# MK20D5 register map
Vendor: Freescale Semiconductor, Inc.; Series: Kinetis_K; File version: 1.6
CPU: CM4 r0p1, little endian, no MPU, no FPU, VTOR, 4 interrupt priority bits
Registers are 32-bit, read-write, reset 0x0 unless marked. A register's access mark holds for its fields unless they carry their own. Offsets are from the block's base; [hi:lo] are bit positions; {n}, {i} and the like mark numbered series; 'fields as' and 'values as' point back to an identical list.

## PORTA — Pin Control and Interrupts
Base 0x40049000; register names take the prefix PORTA_
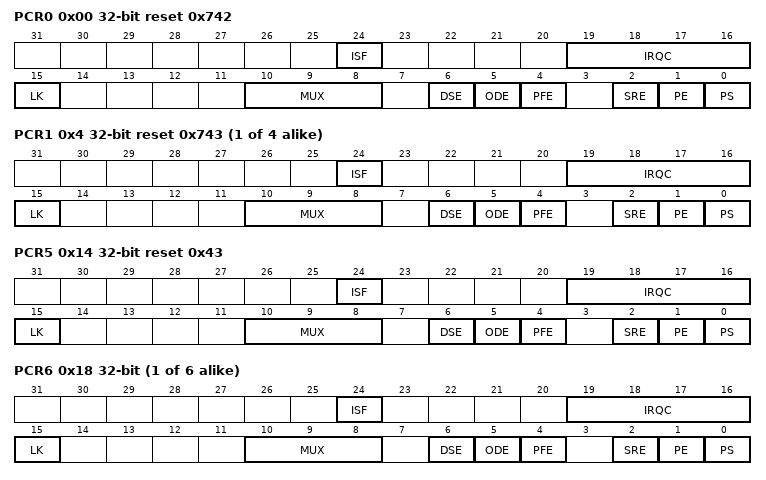
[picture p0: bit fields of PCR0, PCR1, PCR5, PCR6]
0x00 PCR0 reset 0x742 — Pin Control Register n
  [24] ISF — Interrupt Status Flag
    0=Configured interrupt has not been detected; 1=Configured interrupt has been detected. If pin is configured to generate a DMA request then the corresponding flag will be cleared automatically at the completion of the requested DMA transfer, otherwise the flag remains set until a logic one is written to that flag. If configured for a level sensitive interrupt that remains asserted then flag will set again immediately.
  [19:16] IRQC — Interrupt Configuration
    0=Interrupt/DMA Request disabled; 1=DMA Request on rising edge; 2=DMA Request on falling edge; 3=DMA Request on either edge; 8=Interrupt when logic zero; 9=Interrupt on rising edge; 10=Interrupt on falling edge; 11=Interrupt on either edge; 12=Interrupt when logic one
  [15] LK — Lock Register
    0=Pin Control Register bits [15:0] are not locked; 1=Pin Control Register bits [15:0] are locked and cannot be updated until the next System Reset
  [10:8] MUX — Pin Mux Control
    0=Pin Disabled (Analog); 1=Alternative 1 (GPIO); {v}=Alternative {v} (chip specific) (v=2..6); 7=Alternative 7 (chip specific / JTAG / NMI)
  [6] DSE — Drive Strength Enable
    0=Low drive strength is configured on the corresponding pin, if pin is configured as a digital output; 1=High drive strength is configured on the corresponding pin, if pin is configured as a digital output
  [5] ODE — Open Drain Enable
    0=Open Drain output is disabled on the corresponding pin; 1=Open Drain output is enabled on the corresponding pin, provided pin is configured as a digital output
  [4] PFE — Passive Filter Enable
    0=Passive Input Filter is disabled on the corresponding pin; 1=Passive Input Filter is enabled on the corresponding pin, provided pin is configured as a digital input. A low pass filter (10 MHz to 30 MHz bandwidth) is enabled on the digital input path. Disable the Passive Input Filter when supporting high speed interfaces (> 2 MHz) on the pin.
  [2] SRE — Slew Rate Enable
    0=Fast slew rate is configured on the corresponding pin, if pin is configured as a digital output; 1=Slow slew rate is configured on the corresponding pin, if pin is configured as a digital output
  [1] PE — Pull Enable
    0=Internal pull-up or pull-down resistor is not enabled on the corresponding pin; 1=Internal pull-up or pull-down resistor is enabled on the corresponding pin, provided pin is configured as a digital input
  [0] PS — Pull Select
    0=Internal pull-down resistor is enabled on the corresponding pin, if the corresponding Port Pull Enable Register bit is set; 1=Internal pull-up resistor is enabled on the corresponding pin, if the corresponding Port Pull Enable Register bit is set
{0x0+4i} PCR{i} reset 0x743 (i=1..4) — Pin Control Register n
  fields as PCR0
0x14 PCR5 reset 0x43 — Pin Control Register n
  fields as PCR0
{0x0+4i} PCR{i} (i=6..11) — Pin Control Register n
  [24] ISF — Interrupt Status Flag
    values as PCR0.ISF
  [19:16] IRQC — Interrupt Configuration
    values as PCR0.IRQC
  [15] LK — Lock Register
    values as PCR0.LK
  [10:8] MUX — Pin Mux Control
    values as PCR0.MUX
  [6] DSE ro — Drive Strength Enable
    values as PCR0.DSE
  [5] ODE ro — Open Drain Enable
    values as PCR0.ODE
  [4] PFE ro — Passive Filter Enable
    values as PCR0.PFE
  [2] SRE ro — Slew Rate Enable
    values as PCR0.SRE
  [1] PE ro — Pull Enable
    values as PCR0.PE
  [0] PS ro — Pull Select
    values as PCR0.PS
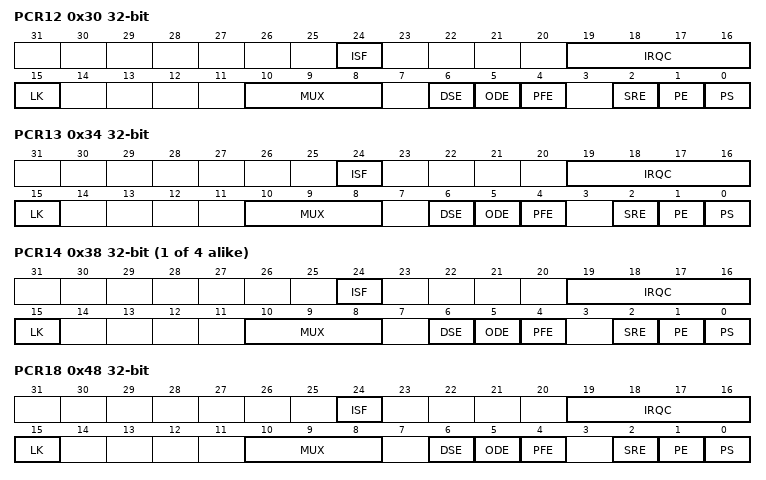
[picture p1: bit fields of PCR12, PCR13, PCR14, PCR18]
0x30 PCR12 — Pin Control Register n
  fields as PCR0
0x34 PCR13 — Pin Control Register n
  fields as PCR0
{0x0+4i} PCR{i} (i=14..17) — Pin Control Register n
  fields as PCR6
0x48 PCR18 — Pin Control Register n
  fields as PCR0
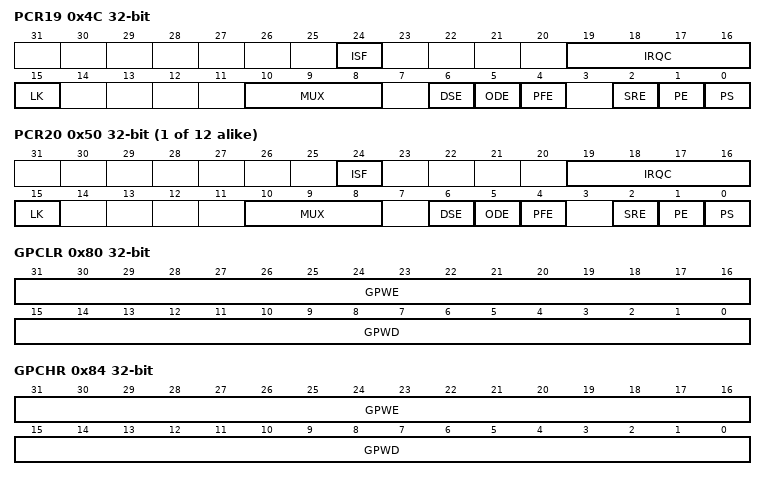
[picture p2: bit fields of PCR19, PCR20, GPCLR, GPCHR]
0x4C PCR19 — Pin Control Register n
  fields as PCR0
{0x0+4i} PCR{i} (i=20..31) — Pin Control Register n
  fields as PCR6
0x80 GPCLR wo — Global Pin Control Low Register
  [31:16] GPWE — Global Pin Write Enable
  [15:0] GPWD — Global Pin Write Data
0x84 GPCHR wo — Global Pin Control High Register
  fields as GPCLR
0xA0 ISFR — Interrupt Status Flag Register
  [31:0] ISF — Interrupt Status Flag
    0=Configured interrupt has not been detected; 1=Configured interrupt has been detected. If pin is configured to generate a DMA request then the corresponding flag will be cleared automatically at the completion of the requested DMA transfer, otherwise the flag remains set until a logic one is written to the flag. If configured for a level sensitive interrupt and the pin remains asserted then the flag will set again immediately after it is cleared.

## PORTB — Pin Control and Interrupts
Base 0x4004A000; register names take the prefix PORTB_
Registers as PORTA; these are added or differ:
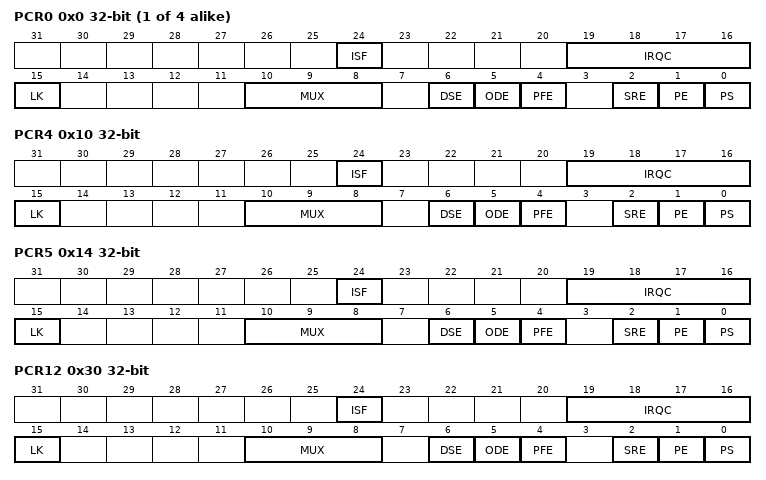
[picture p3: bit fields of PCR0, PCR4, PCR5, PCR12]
{0x0+4i} PCR{i} (i=0..3) — Pin Control Register n
  fields as PORTA.PCR0
0x10 PCR4 — Pin Control Register n
  fields as PORTA.PCR6
0x14 PCR5 — Pin Control Register n
  fields as PORTA.PCR6
0x30 PCR12 — Pin Control Register n
  fields as PORTA.PCR6
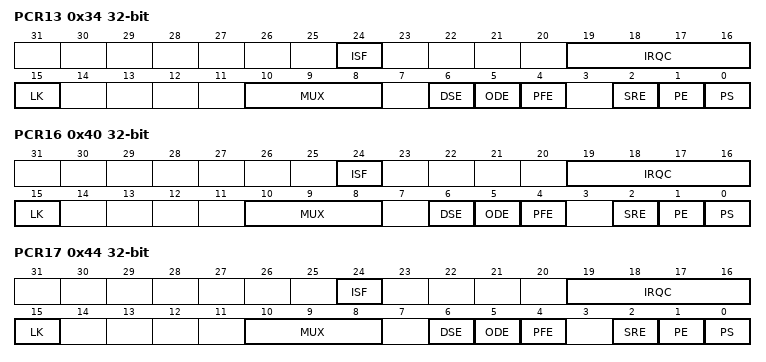
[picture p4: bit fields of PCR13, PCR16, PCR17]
0x34 PCR13 — Pin Control Register n
  fields as PORTA.PCR6
0x40 PCR16 — Pin Control Register n
  fields as PORTA.PCR0
0x44 PCR17 — Pin Control Register n
  fields as PORTA.PCR0

## PORTC — Pin Control and Interrupts
Base 0x4004B000; register names take the prefix PORTC_
Registers as PORTB; these are added or differ:
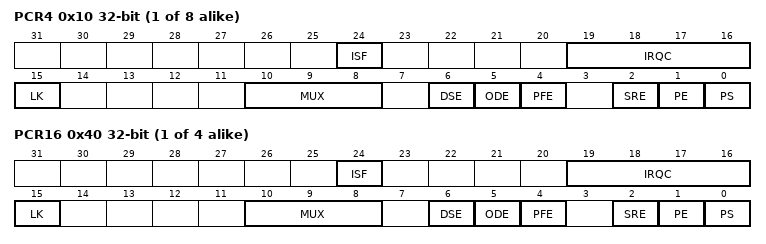
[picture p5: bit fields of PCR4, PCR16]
{0x0+4i} PCR{i} (i=4..11) — Pin Control Register n
  fields as PORTA.PCR0
{0x0+4i} PCR{i} (i=16..19) — Pin Control Register n
  fields as PORTA.PCR6

## PORTD — Pin Control and Interrupts
Base 0x4004C000; register names take the prefix PORTD_
Registers as PORTC; these are added or differ:
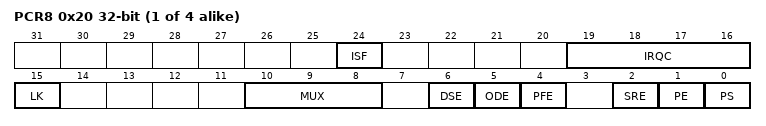
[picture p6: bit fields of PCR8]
{0x0+4i} PCR{i} (i=8..11) — Pin Control Register n
  fields as PORTA.PCR6
0xC0 DFER — Digital Filter Enable Register
  [31:0] DFE — Digital Filter Enable
    0=Digital Filter is disabled on the corresponding pin and output of the digital filter is reset to zero.Each bit in the field enables the digital filter of the same number as the bit; 1=Digital Filter is enabled on the corresponding pin, provided pin is configured as a digital input
0xC4 DFCR — Digital Filter Clock Register
  [0] CS — Clock Source
    0=Digital Filters are clocked by the bus clock; 1=Digital Filters are clocked by the 1 kHz LPO clock
0xC8 DFWR — Digital Filter Width Register
  [4:0] FILT — Filter Length

## PORTE — Pin Control and Interrupts
Base 0x4004D000; register names take the prefix PORTE_
Registers as PORTD, without DFER, DFCR, DFWR; these are added or differ:
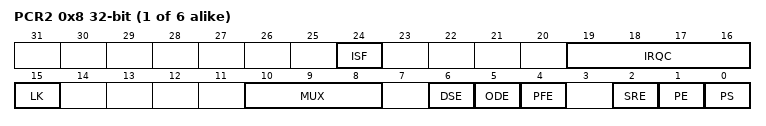
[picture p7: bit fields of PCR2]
{0x0+4i} PCR{i} (i=2..7) — Pin Control Register n
  fields as PORTA.PCR6

## Notices in the file
Redistribution and use in source and binary forms, with or without modification,
are permitted provided that the following conditions are met:
o Redistributions of source code must retain the above copyright notice, this list
of conditions and the following disclaimer.
o Redistributions in binary form must reproduce the above copyright notice, this
list of conditions and the following disclaimer in the documentation and/or
other materials provided with the distribution.
o Neither the name of Freescale Semiconductor, Inc. nor the names of its
contributors may be used to endorse or promote products derived from this
software without specific prior written permission.
THIS SOFTWARE IS PROVIDED BY THE COPYRIGHT HOLDERS AND CONTRIBUTORS "AS IS" AND
ANY EXPRESS OR IMPLIED WARRANTIES, INCLUDING, BUT NOT LIMITED TO, THE IMPLIED
WARRANTIES OF MERCHANTABILITY AND FITNESS FOR A PARTICULAR PURPOSE ARE
DISCLAIMED. IN NO EVENT SHALL THE COPYRIGHT HOLDER OR CONTRIBUTORS BE LIABLE FOR
ANY DIRECT, INDIRECT, INCIDENTAL, SPECIAL, EXEMPLARY, OR CONSEQUENTIAL DAMAGES
(INCLUDING, BUT NOT LIMITED TO, PROCUREMENT OF SUBSTITUTE GOODS OR SERVICES;
LOSS OF USE, DATA, OR PROFITS; OR BUSINESS INTERRUPTION) HOWEVER CAUSED AND ON
ANY THEORY OF LIABILITY, WHETHER IN CONTRACT, STRICT LIABILITY, OR TORT
(INCLUDING NEGLIGENCE OR OTHERWISE) ARISING IN ANY WAY OUT OF THE USE OF THIS
SOFTWARE, EVEN IF ADVISED OF THE POSSIBILITY OF SUCH DAMAGE.
